AUTOSAR XML (schema 314)
package /ComponentType
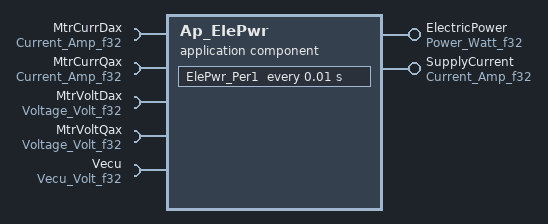
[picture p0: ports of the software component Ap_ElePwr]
  application software component type Ap_ElePwr
    provide port ElectricPower: unqueued-sender-com-spec{data-element=Watt_f32, can-invalidate=false, init-value=D_ZERO_ULS_F32}, provided-interface=Power_Watt_f32
    provide port SupplyCurrent: unqueued-sender-com-spec{data-element=Amp_f32, can-invalidate=false, init-value=D_ZERO_ULS_F32}, provided-interface=Current_Amp_f32
    5 x require port:
      MtrCurrDax: unqueued-receiver-com-spec{data-element=Amp_f32, init-value=D_ZERO_ULS_F32}, required-interface=Current_Amp_f32
      MtrCurrQax: unqueued-receiver-com-spec{data-element=Amp_f32, init-value=D_ZERO_ULS_F32}, required-interface=Current_Amp_f32
      MtrVoltDax: unqueued-receiver-com-spec{data-element=Volt_f32, init-value=D_ZERO_ULS_F32}, required-interface=Voltage_Volt_f32
      MtrVoltQax: unqueued-receiver-com-spec{data-element=Volt_f32, init-value=D_ZERO_ULS_F32}, required-interface=Voltage_Volt_f32
      Vecu: unqueued-receiver-com-spec{data-element=Volt_f32, init-value=D_VECUMIN_VOLTS_F32}, required-interface=Vecu_Volt_f32
  internal behavior Ap_ElePwr_InternalBehavior: component=Ap_ElePwr
    timing event TMT_ElePwr_Per1: start-on-event=ElePwr_Per1, period=0.01
    port-api-options:
      enable-take-address=false, indirect-api=false, port=ElectricPower
      enable-take-address=false, indirect-api=false, port=MtrCurrDax
      enable-take-address=false, indirect-api=false, port=MtrCurrQax
      enable-take-address=false, indirect-api=false, port=MtrVoltDax
      enable-take-address=false, indirect-api=false, port=MtrVoltQax
      enable-take-address=false, indirect-api=false, port=SupplyCurrent
      enable-take-address=false, indirect-api=false, port=Vecu
    runnable ElePwr_Per1
      5 x data read access:
        READ_MtrCurrDax_Amp_f32: data-element=MtrCurrDax.Amp_f32
        READ_MtrCurrQax_Amp_f32: data-element=MtrCurrQax.Amp_f32
        READ_MtrVoltDax_Volt_f32: data-element=MtrVoltDax.Volt_f32
        READ_MtrVoltQax_Volt_f32: data-element=MtrVoltQax.Volt_f32
        READ_Vecu_Volt_f32: data-element=Vecu.Volt_f32
      data write access WRITE_ElectricPower_Watt_f32: data-element=ElectricPower.Watt_f32
      data write access WRITE_SupplyCurrent_Amp_f32: data-element=SupplyCurrent.Amp_f32
  swc implementation Ap_ElePwr_Implementation: behavior=Ap_ElePwr_InternalBehavior
    code-descriptors:
      code Code: type=SRC
